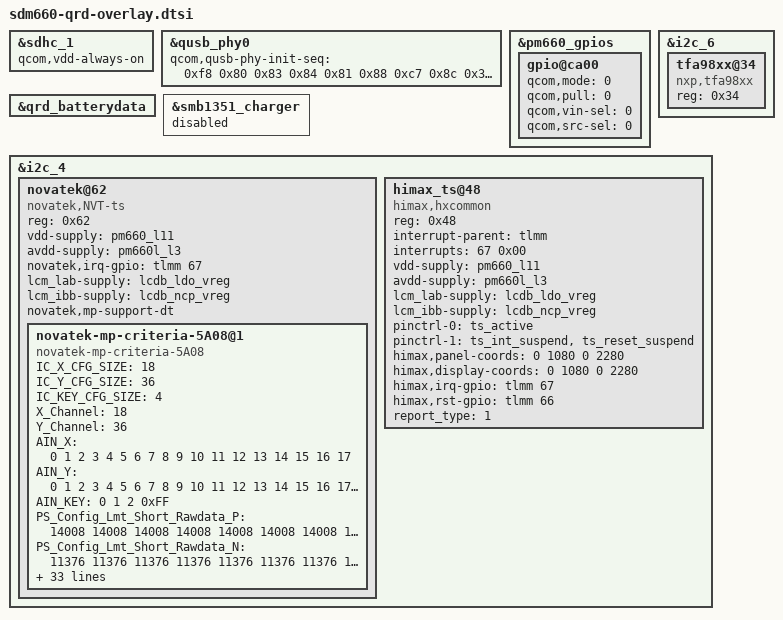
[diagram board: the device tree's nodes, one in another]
/* SPDX-License-Identifier: GPL-2.0 */

#include "sdm660-pinctrl-overlay.dtsi"
#include "sdm660-camera-sensor-qrd-overlay.dtsi"

&sdhc_1 {
	qcom,vdd-always-on;
};

&qusb_phy0 {
	qcom,qusb-phy-init-seq = <0xf8 0x80
				0x83 0x84
				0x81 0x88
				0xc7 0x8c
				0x30 0x08
				0x79 0x0c
				0x21 0x10
				0x14 0x9c
				0x9f 0x1c
				0x00 0x18>;
};

&pm660_gpios {
	gpio@ca00 {
		status = "okay";
		qcom,mode = <0>;
		qcom,pull = <0>;
		qcom,vin-sel = <0>;
		qcom,src-sel = <0>;
		/delete-property/ qcom,out-strength;
	};
};

&i2c_6 {
	tfa98xx@34 {
		compatible = "nxp,tfa98xx";
		reg = <0x34>;
	};
};

&qrd_batterydata {
	/delete-node/ qcom,qrd_msm8998_skuk_3000mah;

	#include "fg-gen3-batterydata-3292665_Huaqin_QL1650cos_5000mAh.dtsi"
};

&smb1351_charger {
	status = "disabled";
};

&i2c_4{
	status = "ok";

	/* Novatek device tree node */
	novatek@62 {
		compatible = "novatek,NVT-ts";
		reg = <0x62>;
		status = "ok";

		vdd-supply = <&pm660_l11>;    //VDDIO
		avdd-supply = <&pm660l_l3>;    //VDD

		novatek,irq-gpio = <&tlmm 67 0>;

		lcm_lab-supply = <&lcdb_ldo_vreg>;
		lcm_ibb-supply = <&lcdb_ncp_vreg>;

		/* MP */
		novatek,mp-support-dt;

		novatek-mp-criteria-5A08@1 {
			#address-cells = <1>;
			#size-cells = <0>;
			compatible = "novatek-mp-criteria-5A08";

			/* MP Config */
			IC_X_CFG_SIZE = <18>;
			IC_Y_CFG_SIZE = <36>;
			IC_KEY_CFG_SIZE = <4>;
			X_Channel = <18>;
			Y_Channel = <36>;
			AIN_X = <0 1 2 3 4 5 6 7 8 9 10 11 12 13 14 15 16 17>;
			AIN_Y = <0 1 2 3 4 5 6 7 8 9 10 11 12 13 14 15 16 17 18 19 20 21 22 23 24 25 26 27 28 29 30 31 32 33 34 35>;
			AIN_KEY = <0 1 2 0xFF>;

			/* MP Criteria */
			PS_Config_Lmt_Short_Rawdata_P = <
				14008 14008 14008 14008 14008 14008 14008 14008 14008 14008 14008 14008 14008 14008 14008 14008 14008 14008
				14008 14008 14008 14008 14008 14008 14008 14008 14008 14008 14008 14008 14008 14008 14008 14008 14008 14008
				14008 14008 14008 14008 14008 14008 14008 14008 14008 14008 14008 14008 14008 14008 14008 14008 14008 14008
				14008 14008 14008 14008 14008 14008 14008 14008 14008 14008 14008 14008 14008 14008 14008 14008 14008 14008
				14008 14008 14008 14008 14008 14008 14008 14008 14008 14008 14008 14008 14008 14008 14008 14008 14008 14008
				14008 14008 14008 14008 14008 14008 14008 14008 14008 14008 14008 14008 14008 14008 14008 14008 14008 14008
				14008 14008 14008 14008 14008 14008 14008 14008 14008 14008 14008 14008 14008 14008 14008 14008 14008 14008
				14008 14008 14008 14008 14008 14008 14008 14008 14008 14008 14008 14008 14008 14008 14008 14008 14008 14008
				14008 14008 14008 14008 14008 14008 14008 14008 14008 14008 14008 14008 14008 14008 14008 14008 14008 14008
				14008 14008 14008 14008 14008 14008 14008 14008 14008 14008 14008 14008 14008 14008 14008 14008 14008 14008
				14008 14008 14008 14008 14008 14008 14008 14008 14008 14008 14008 14008 14008 14008 14008 14008 14008 14008
				14008 14008 14008 14008 14008 14008 14008 14008 14008 14008 14008 14008 14008 14008 14008 14008 14008 14008
				14008 14008 14008 14008 14008 14008 14008 14008 14008 14008 14008 14008 14008 14008 14008 14008 14008 14008
				14008 14008 14008 14008 14008 14008 14008 14008 14008 14008 14008 14008 14008 14008 14008 14008 14008 14008
				14008 14008 14008 14008 14008 14008 14008 14008 14008 14008 14008 14008 14008 14008 14008 14008 14008 14008
				14008 14008 14008 14008 14008 14008 14008 14008 14008 14008 14008 14008 14008 14008 14008 14008 14008 14008
				14008 14008 14008 14008 14008 14008 14008 14008 14008 14008 14008 14008 14008 14008 14008 14008 14008 14008
				14008 14008 14008 14008 14008 14008 14008 14008 14008 14008 14008 14008 14008 14008 14008 14008 14008 14008
				14008 14008 14008 14008 14008 14008 14008 14008 14008 14008 14008 14008 14008 14008 14008 14008 14008 14008
				14008 14008 14008 14008 14008 14008 14008 14008 14008 14008 14008 14008 14008 14008 14008 14008 14008 14008
				14008 14008 14008 14008 14008 14008 14008 14008 14008 14008 14008 14008 14008 14008 14008 14008 14008 14008
				14008 14008 14008 14008 14008 14008 14008 14008 14008 14008 14008 14008 14008 14008 14008 14008 14008 14008
				14008 14008 14008 14008 14008 14008 14008 14008 14008 14008 14008 14008 14008 14008 14008 14008 14008 14008
				14008 14008 14008 14008 14008 14008 14008 14008 14008 14008 14008 14008 14008 14008 14008 14008 14008 14008
				14008 14008 14008 14008 14008 14008 14008 14008 14008 14008 14008 14008 14008 14008 14008 14008 14008 14008
				14008 14008 14008 14008 14008 14008 14008 14008 14008 14008 14008 14008 14008 14008 14008 14008 14008 14008
				14008 14008 14008 14008 14008 14008 14008 14008 14008 14008 14008 14008 14008 14008 14008 14008 14008 14008
				14008 14008 14008 14008 14008 14008 14008 14008 14008 14008 14008 14008 14008 14008 14008 14008 14008 14008
				14008 14008 14008 14008 14008 14008 14008 14008 14008 14008 14008 14008 14008 14008 14008 14008 14008 14008
				14008 14008 14008 14008 14008 14008 14008 14008 14008 14008 14008 14008 14008 14008 14008 14008 14008 14008
				14008 14008 14008 14008 14008 14008 14008 14008 14008 14008 14008 14008 14008 14008 14008 14008 14008 14008
				14008 14008 14008 14008 14008 14008 14008 14008 14008 14008 14008 14008 14008 14008 14008 14008 14008 14008
				14008 14008 14008 14008 14008 14008 14008 14008 14008 14008 14008 14008 14008 14008 14008 14008 14008 14008
				14008 14008 14008 14008 14008 14008 14008 14008 14008 14008 14008 14008 14008 14008 14008 14008 14008 14008
				14008 14008 14008 14008 14008 14008 14008 14008 14008 14008 14008 14008 14008 14008 14008 14008 14008 14008
				14008 14008 14008 14008 14008 14008 14008 14008 14008 14008 14008 14008 14008 14008 14008 14008 14008 14008
				20000 20000 20000>;

			PS_Config_Lmt_Short_Rawdata_N = <
				11376 11376 11376 11376 11376 11376 11376 11376 11376 11376 11376 11376 11376 11376 11376 11376 11376 11376
				11376 11376 11376 11376 11376 11376 11376 11376 11376 11376 11376 11376 11376 11376 11376 11376 11376 11376
				11376 11376 11376 11376 11376 11376 11376 11376 11376 11376 11376 11376 11376 11376 11376 11376 11376 11376
				11376 11376 11376 11376 11376 11376 11376 11376 11376 11376 11376 11376 11376 11376 11376 11376 11376 11376
				11376 11376 11376 11376 11376 11376 11376 11376 11376 11376 11376 11376 11376 11376 11376 11376 11376 11376
				11376 11376 11376 11376 11376 11376 11376 11376 11376 11376 11376 11376 11376 11376 11376 11376 11376 11376
				11376 11376 11376 11376 11376 11376 11376 11376 11376 11376 11376 11376 11376 11376 11376 11376 11376 11376
				11376 11376 11376 11376 11376 11376 11376 11376 11376 11376 11376 11376 11376 11376 11376 11376 11376 11376
				11376 11376 11376 11376 11376 11376 11376 11376 11376 11376 11376 11376 11376 11376 11376 11376 11376 11376
				11376 11376 11376 11376 11376 11376 11376 11376 11376 11376 11376 11376 11376 11376 11376 11376 11376 11376
				11376 11376 11376 11376 11376 11376 11376 11376 11376 11376 11376 11376 11376 11376 11376 11376 11376 11376
				11376 11376 11376 11376 11376 11376 11376 11376 11376 11376 11376 11376 11376 11376 11376 11376 11376 11376
				11376 11376 11376 11376 11376 11376 11376 11376 11376 11376 11376 11376 11376 11376 11376 11376 11376 11376
				11376 11376 11376 11376 11376 11376 11376 11376 11376 11376 11376 11376 11376 11376 11376 11376 11376 11376
				11376 11376 11376 11376 11376 11376 11376 11376 11376 11376 11376 11376 11376 11376 11376 11376 11376 11376
				11376 11376 11376 11376 11376 11376 11376 11376 11376 11376 11376 11376 11376 11376 11376 11376 11376 11376
				11376 11376 11376 11376 11376 11376 11376 11376 11376 11376 11376 11376 11376 11376 11376 11376 11376 11376
				11376 11376 11376 11376 11376 11376 11376 11376 11376 11376 11376 11376 11376 11376 11376 11376 11376 11376
				11376 11376 11376 11376 11376 11376 11376 11376 11376 11376 11376 11376 11376 11376 11376 11376 11376 11376
				11376 11376 11376 11376 11376 11376 11376 11376 11376 11376 11376 11376 11376 11376 11376 11376 11376 11376
				11376 11376 11376 11376 11376 11376 11376 11376 11376 11376 11376 11376 11376 11376 11376 11376 11376 11376
				11376 11376 11376 11376 11376 11376 11376 11376 11376 11376 11376 11376 11376 11376 11376 11376 11376 11376
				11376 11376 11376 11376 11376 11376 11376 11376 11376 11376 11376 11376 11376 11376 11376 11376 11376 11376
				11376 11376 11376 11376 11376 11376 11376 11376 11376 11376 11376 11376 11376 11376 11376 11376 11376 11376
				11376 11376 11376 11376 11376 11376 11376 11376 11376 11376 11376 11376 11376 11376 11376 11376 11376 11376
				11376 11376 11376 11376 11376 11376 11376 11376 11376 11376 11376 11376 11376 11376 11376 11376 11376 11376
				11376 11376 11376 11376 11376 11376 11376 11376 11376 11376 11376 11376 11376 11376 11376 11376 11376 11376
				11376 11376 11376 11376 11376 11376 11376 11376 11376 11376 11376 11376 11376 11376 11376 11376 11376 11376
				11376 11376 11376 11376 11376 11376 11376 11376 11376 11376 11376 11376 11376 11376 11376 11376 11376 11376
				11376 11376 11376 11376 11376 11376 11376 11376 11376 11376 11376 11376 11376 11376 11376 11376 11376 11376
				11376 11376 11376 11376 11376 11376 11376 11376 11376 11376 11376 11376 11376 11376 11376 11376 11376 11376
				11376 11376 11376 11376 11376 11376 11376 11376 11376 11376 11376 11376 11376 11376 11376 11376 11376 11376
				11376 11376 11376 11376 11376 11376 11376 11376 11376 11376 11376 11376 11376 11376 11376 11376 11376 11376
				11376 11376 11376 11376 11376 11376 11376 11376 11376 11376 11376 11376 11376 11376 11376 11376 11376 11376
				11376 11376 11376 11376 11376 11376 11376 11376 11376 11376 11376 11376 11376 11376 11376 11376 11376 11376
				11376 11376 11376 11376 11376 11376 11376 11376 11376 11376 11376 11376 11376 11376 11376 11376 11376 11376
				11550 11550 11550>;

			PS_Config_Lmt_Short_Diff_P = <
				6300 6300 6300 6300 6300 6300 6300 6300 6300 6300 6300 6300 6300 6300 6300 6300 6300 6300
				6300 6300 6300>;

			PS_Config_Lmt_Short_Diff_N = <
				0 0 0 0 0 0 0 0 0 0 0 0 0 0 0 0 0 0
				0 0 0>;

			PS_Config_Lmt_Short_Base_P = <
				2000 2000 2000 2000 2000 2000 2000 2000 2000 2000 2000 2000 2000 2000 2000 2000 2000 2000
				2000 2000 2000>;

			PS_Config_Lmt_Short_Base_N = <
				(-2000) (-2000) (-2000) (-2000) (-2000) (-2000) (-2000) (-2000) (-2000) (-2000) (-2000) (-2000) (-2000) (-2000) (-2000) (-2000) (-2000) (-2000)
				(-2000) (-2000) (-2000)>;

			PS_Config_Lmt_Open_Rawdata_P = <
				65535 6394 6393 6394 6394 6394 6394 65535 65535 65535 65535 6377 6377 6379 6379 6379 6379 65535
				3176 3307 3299 3291 3283 3271 3120 2645 2601 2558 2607 3086 3245 3261 3278 3310 3333 3205
				3141 3240 3236 3227 3219 3209 3137 3133 3109 3099 3132 3132 3210 3226 3240 3274 3298 3208
				3131 3213 3212 3204 3197 3188 3118 3115 3094 3053 3086 3084 3160 3172 3190 3223 3247 3172
				3162 3220 3217 3209 3203 3196 3127 3123 3102 3070 3100 3097 3171 3185 3200 3234 3259 3211
				3187 3231 3227 3221 3217 3210 3141 3139 3118 3073 3103 3099 3172 3184 3200 3233 3259 3225
				3251 3264 3262 3256 3249 3244 3177 3175 3157 3127 3156 3154 3229 3244 3257 3287 3314 3309
				3221 3219 3217 3216 3210 3206 3141 3145 3123 3083 3116 3111 3182 3193 3208 3237 3264 3275
				3232 3212 3214 3211 3205 3202 3140 3123 3120 3086 3093 3107 3175 3188 3199 3230 3257 3287
				3247 3214 3216 3217 3212 3208 3148 3130 3128 3074 3082 3095 3161 3172 3186 3213 3241 3283
				3279 3235 3236 3236 3233 3230 3170 3158 3155 3124 3129 3142 3211 3223 3234 3260 3288 3341
				3234 3174 3173 3177 3174 3173 3116 3108 3104 3069 3067 3079 3144 3153 3167 3188 3222 3287
				3232 3157 3158 3161 3159 3160 3103 3096 3090 3055 3053 3059 3125 3134 3146 3161 3193 3282
				3229 3148 3147 3154 3151 3154 3096 3095 3084 3033 3031 3037 3105 3110 3125 3138 3169 3261
				3251 3184 3152 3156 3157 3163 3101 3105 3095 3070 3059 3070 3142 3147 3159 3175 3208 3310
				3207 3400 3124 3106 3106 3113 3053 3059 3048 3005 3000 3008 3077 3079 3093 3107 3302 3247
				3188 3371 3366 3372 3104 3086 3028 3034 3021 2986 2989 2991 3056 3059 3245 3382 3404 3236
				3177 3349 3346 3353 3355 3093 3008 3006 3002 2941 2936 2947 3011 3190 3326 3339 3356 3200
				3186 3336 3319 3317 3309 3313 2949 2946 2935 2977 2958 2959 3318 3312 3314 3318 3335 3187
				3127 3272 3256 3256 3248 3251 2887 2883 2887 2903 2885 2884 3245 3241 3242 3245 3259 3115
				3113 3247 3229 3230 3225 3230 2864 2859 2857 2875 2850 2853 3220 3212 3212 3213 3225 3094
				3088 3217 3202 3201 3197 3203 2833 2831 2823 2834 2807 2811 3181 3172 3172 3174 3180 3053
				3072 3196 3177 3177 3176 3184 2814 2811 2799 2849 2825 2830 3198 3191 3190 3190 3195 3076
				3011 3127 3111 3110 3110 3117 2745 2748 2732 2759 2737 2742 3112 3103 3101 3102 3104 2990
				2982 3089 3068 3061 3061 3069 2695 2697 2676 2712 2693 2696 3068 3060 3057 3058 3062 2954
				2959 3064 3047 3037 3039 3048 2672 2679 2653 2662 2657 2654 3028 3019 3014 3018 3017 2908
				2942 3039 3021 3011 3014 3023 2645 2655 2621 2667 2669 2661 3035 3027 3024 3025 3026 2923
				2863 2960 2943 2931 2934 2933 2564 2583 2541 2556 2578 2568 2937 2936 2933 2934 2933 2828
				2828 2924 2905 2895 2898 2896 2526 2529 2501 2512 2535 2526 2895 2896 2895 2893 2893 2787
				2792 2883 2865 2853 2856 2852 2479 2486 2458 2442 2468 2459 2829 2832 2832 2831 2831 2724
				2725 2813 2794 2782 2782 2778 2403 2411 2381 2412 2435 2427 2798 2802 2803 2802 2804 2702
				2686 2773 2757 2745 2744 2738 2365 2373 2342 2346 2372 2365 2739 2743 2743 2742 2743 2640
				2643 2728 2710 2699 2698 2690 2317 2320 2291 2300 2327 2321 2696 2701 2703 2700 2703 2600
				2605 2690 2675 2664 2660 2651 2281 2284 2253 2233 2263 2255 2630 2635 2640 2637 2639 2535
				2550 2635 2617 2605 2602 2593 2218 2219 2191 2208 2239 2233 2606 2614 2623 2620 2620 2518
				2616 2753 2732 2723 2718 2713 2334 2331 2304 2301 2332 2330 2705 2711 2723 2719 2719 2525
				13000 13000 13000>;

			PS_Config_Lmt_Open_Rawdata_N = <
				(-65535) 3221 3221 3221 3221 3221 3221 (-65535) (-65535) (-65535) (-65535) 3213 3213 3214 3214 3214 3214 (-65535)
				1600 1666 1662 1658 1654 1648 1572 1333 1310 1288 1314 1555 1635 1643 1651 1667 1679 1615
				1582 1632 1630 1626 1622 1616 1580 1578 1566 1561 1578 1578 1617 1625 1632 1649 1661 1616
				1577 1619 1618 1614 1611 1606 1571 1569 1559 1538 1555 1554 1592 1598 1607 1624 1636 1598
				1593 1622 1621 1617 1614 1610 1575 1573 1563 1547 1561 1560 1598 1605 1612 1629 1642 1618
				1606 1627 1626 1623 1620 1617 1582 1581 1571 1548 1563 1561 1598 1604 1612 1629 1642 1625
				1638 1645 1644 1640 1637 1634 1601 1600 1590 1575 1590 1589 1627 1634 1641 1656 1669 1667
				1623 1622 1621 1620 1617 1615 1582 1584 1573 1553 1570 1567 1603 1608 1616 1631 1644 1650
				1628 1618 1619 1617 1615 1613 1582 1573 1572 1555 1558 1565 1599 1606 1611 1627 1641 1656
				1636 1619 1620 1620 1618 1616 1586 1577 1576 1549 1552 1559 1592 1598 1605 1619 1633 1654
				1652 1630 1630 1630 1629 1627 1597 1591 1590 1574 1576 1583 1617 1624 1629 1642 1656 1683
				1629 1599 1598 1601 1599 1598 1570 1566 1564 1546 1545 1551 1584 1588 1595 1606 1623 1656
				1628 1591 1591 1593 1591 1592 1563 1560 1556 1539 1538 1541 1574 1579 1585 1592 1609 1653
				1627 1586 1585 1589 1587 1589 1559 1559 1554 1528 1527 1530 1564 1567 1574 1581 1596 1643
				1638 1604 1588 1590 1590 1593 1562 1564 1559 1546 1541 1547 1583 1585 1591 1599 1616 1667
				1616 1713 1574 1565 1564 1568 1538 1541 1535 1514 1511 1515 1550 1551 1558 1565 1664 1636
				1606 1698 1696 1699 1563 1555 1525 1529 1522 1504 1506 1507 1540 1541 1634 1704 1715 1630
				1601 1687 1685 1689 1690 1558 1515 1514 1512 1482 1479 1485 1517 1607 1676 1682 1691 1612
				1605 1681 1672 1671 1667 1669 1486 1484 1478 1500 1490 1491 1671 1669 1670 1671 1680 1606
				1575 1648 1640 1640 1636 1638 1454 1452 1454 1462 1453 1453 1634 1633 1633 1635 1642 1569
				1568 1636 1627 1627 1625 1627 1443 1440 1439 1448 1436 1437 1622 1618 1618 1618 1625 1559
				1556 1621 1613 1612 1611 1614 1427 1426 1422 1427 1414 1416 1602 1598 1598 1599 1602 1538
				1548 1610 1600 1600 1600 1604 1417 1416 1410 1435 1423 1426 1611 1607 1607 1607 1610 1550
				1517 1575 1567 1567 1567 1570 1383 1384 1376 1390 1379 1381 1568 1563 1562 1563 1564 1506
				1502 1556 1546 1542 1542 1546 1358 1359 1348 1366 1357 1358 1545 1542 1540 1540 1542 1488
				1491 1544 1535 1530 1531 1535 1346 1350 1336 1341 1339 1337 1525 1521 1518 1520 1520 1465
				1482 1531 1522 1517 1519 1523 1332 1338 1320 1343 1344 1340 1529 1525 1523 1524 1524 1472
				1442 1491 1483 1477 1478 1478 1292 1301 1280 1288 1299 1294 1479 1479 1478 1478 1477 1425
				1425 1473 1464 1458 1460 1459 1273 1274 1260 1265 1277 1272 1458 1459 1458 1457 1457 1404
				1406 1452 1443 1437 1439 1437 1249 1252 1238 1230 1243 1239 1425 1426 1426 1426 1426 1372
				1373 1417 1408 1402 1402 1399 1211 1214 1199 1215 1227 1223 1410 1412 1412 1411 1413 1361
				1353 1397 1389 1383 1382 1379 1191 1195 1180 1182 1195 1192 1380 1382 1382 1381 1382 1330
				1331 1374 1365 1359 1359 1355 1167 1169 1154 1159 1172 1169 1358 1361 1361 1360 1362 1310
				1312 1355 1348 1342 1340 1336 1149 1151 1135 1125 1140 1136 1325 1327 1330 1328 1329 1277
				1285 1327 1318 1312 1311 1306 1117 1118 1104 1112 1128 1125 1313 1317 1321 1320 1320 1268
				1318 1387 1376 1372 1369 1367 1176 1174 1161 1159 1175 1174 1363 1366 1372 1370 1370 1272
				6500 6500 6500>;

			PS_Config_Lmt_FW_Rawdata_P = <
				65535 1697 1715 1707 1674 1697 1720 65535 65535 65535 65535 1708 1717 1670 1685 1687 1691 65535
				1676 1661 1670 1672 1669 1668 1687 1670 1694 1698 1674 1704 1676 1668 1665 1678 1663 1672
				1684 1694 1687 1702 1676 1663 1671 1710 1686 1692 1662 1663 1685 1716 1659 1696 1686 1699
				1682 1697 1656 1692 1677 1635 1690 1691 1686 1671 1651 1655 1680 1699 1662 1680 1671 1690
				1678 1699 1713 1702 1669 1692 1703 1681 1671 1688 1673 1661 1690 1709 1651 1674 1676 1699
				1711 1702 1682 1726 1691 1684 1712 1698 1679 1709 1678 1693 1717 1715 1691 1697 1684 1703
				1674 1682 1678 1684 1666 1646 1682 1682 1668 1655 1672 1654 1670 1688 1645 1650 1699 1652
				1716 1685 1674 1687 1698 1685 1705 1702 1688 1691 1660 1697 1686 1683 1683 1692 1669 1682
				1662 1670 1704 1688 1681 1697 1689 1662 1678 1704 1671 1672 1680 1706 1669 1677 1701 1687
				1684 1678 1709 1691 1674 1732 1735 1689 1665 1715 1711 1689 1693 1696 1662 1677 1696 1713
				1681 1677 1677 1693 1689 1663 1667 1663 1705 1674 1663 1690 1683 1670 1673 1679 1691 1684
				1695 1702 1684 1680 1705 1678 1676 1679 1688 1678 1668 1671 1660 1687 1689 1677 1686 1703
				1697 1688 1692 1686 1702 1713 1705 1693 1682 1676 1697 1680 1693 1704 1689 1686 1703 1676
				1661 1653 1649 1672 1673 1670 1671 1666 1678 1673 1663 1684 1667 1667 1674 1664 1678 1676
				1660 1696 1686 1705 1694 1697 1681 1685 1677 1716 1686 1709 1703 1679 1695 1681 1714 1706
				1700 1690 1679 1703 1709 1725 1714 1699 1692 1700 1697 1697 1702 1710 1683 1698 1701 1684
				1646 1691 1668 1668 1665 1672 1674 1653 1687 1671 1670 1680 1658 1678 1678 1674 1674 1663
				1697 1677 1664 1696 1684 1714 1708 1702 1689 1693 1687 1689 1685 1676 1721 1696 1693 1700
				1650 1657 1669 1649 1660 1659 1663 1659 1675 1641 1679 1651 1644 1655 1692 1670 1636 1689
				1668 1678 1688 1681 1705 1675 1689 1716 1687 1687 1681 1674 1667 1664 1693 1676 1680 1701
				1658 1658 1701 1694 1672 1685 1683 1681 1686 1673 1703 1702 1698 1712 1691 1661 1678 1708
				1705 1665 1686 1688 1704 1676 1687 1680 1682 1685 1700 1684 1679 1688 1687 1690 1720 1672
				1686 1697 1670 1698 1699 1700 1700 1695 1676 1701 1715 1686 1693 1687 1679 1692 1689 1667
				1658 1682 1679 1657 1673 1694 1657 1647 1664 1648 1683 1675 1683 1678 1668 1664 1690 1681
				1655 1677 1670 1671 1662 1673 1667 1672 1686 1670 1673 1675 1666 1670 1673 1690 1657 1673
				1694 1721 1709 1684 1653 1654 1682 1699 1691 1692 1697 1692 1682 1675 1688 1726 1709 1670
				1694 1679 1643 1680 1719 1711 1691 1678 1661 1675 1694 1703 1673 1673 1705 1699 1685 1675
				1683 1673 1681 1691 1693 1687 1702 1677 1675 1706 1691 1685 1689 1693 1687 1712 1699 1687
				1699 1718 1686 1677 1680 1685 1669 1688 1676 1709 1698 1711 1695 1692 1692 1713 1673 1670
				1674 1677 1671 1675 1688 1682 1698 1671 1675 1664 1702 1692 1704 1695 1669 1709 1709 1691
				1723 1689 1699 1697 1688 1692 1693 1698 1692 1689 1700 1699 1710 1705 1691 1693 1698 1693
				1677 1693 1660 1668 1687 1666 1675 1672 1672 1668 1696 1692 1676 1663 1656 1680 1680 1696
				1634 1666 1688 1691 1694 1683 1690 1665 1677 1675 1707 1676 1689 1692 1682 1674 1674 1676
				1707 1707 1711 1674 1671 1685 1679 1678 1682 1683 1706 1711 1695 1698 1683 1706 1672 1690
				1678 1684 1693 1675 1649 1658 1675 1666 1665 1678 1649 1636 1680 1684 1645 1669 1679 1677
				1684 1677 1672 1682 1661 1666 1673 1664 1674 1673 1665 1668 1669 1665 1677 1659 1665 1671
				2000 2000 2000>;

			PS_Config_Lmt_FW_Rawdata_N = <
				(-65535) 727 735 732 718 727 737 (-65535) (-65535) (-65535) (-65535) 732 736 716 722 723 725 (-65535)
				718 712 716 717 715 715 723 716 726 728 718 730 718 715 713 719 713 716
				722 726 723 730 718 713 716 733 723 725 712 713 722 735 711 727 723 728
				721 727 710 725 719 701 724 725 723 716 707 709 720 728 712 720 716 724
				719 728 734 730 715 725 730 720 716 723 717 712 724 732 708 717 718 728
				733 730 721 740 725 722 734 728 720 733 719 726 736 735 725 727 722 730
				717 721 719 722 714 705 721 721 715 709 716 709 716 724 705 707 728 708
				735 722 718 723 728 722 731 729 724 725 711 727 723 721 721 725 715 721
				712 716 730 723 720 727 724 712 719 730 716 717 720 731 715 719 729 723
				722 719 732 725 717 742 744 724 714 735 733 724 726 727 712 719 727 734
				720 719 719 726 724 713 714 713 731 717 713 724 721 716 717 720 725 722
				727 729 722 720 731 719 718 719 724 719 715 716 711 723 724 719 723 730
				727 724 725 723 729 734 731 725 721 718 727 720 725 730 724 722 730 718
				712 708 707 716 717 716 716 714 719 717 713 722 714 714 717 713 719 718
				712 727 722 731 726 727 721 722 719 736 722 732 730 720 727 720 734 731
				729 724 719 730 733 739 735 728 725 728 727 727 730 733 721 728 729 722
				705 725 715 715 714 717 717 708 723 716 716 720 711 719 719 717 717 713
				727 719 713 727 722 734 732 729 724 725 723 724 722 718 738 727 725 729
				707 710 715 707 711 711 713 711 718 703 720 708 705 709 725 716 701 724
				715 719 723 720 731 718 724 735 723 723 720 718 715 713 726 718 720 729
				711 711 729 726 716 722 721 720 723 717 730 729 728 734 725 712 719 732
				731 714 723 724 730 718 723 720 721 722 728 722 719 723 723 724 737 717
				722 727 716 728 728 728 729 726 718 729 735 722 725 723 720 725 724 714
				711 721 720 710 717 726 710 706 713 706 721 718 721 719 715 713 724 720
				709 719 716 716 712 717 714 717 722 716 717 718 714 716 717 724 710 717
				726 738 732 722 709 709 721 728 725 725 727 725 721 718 723 740 732 716
				726 720 704 720 737 733 725 719 712 718 726 730 717 717 731 728 722 718
				721 717 720 725 726 723 729 719 718 731 725 722 724 725 723 734 728 723
				728 736 723 719 720 722 715 724 718 732 728 733 726 725 725 734 717 716
				718 719 716 718 724 721 728 716 718 713 729 725 730 726 715 733 732 725
				738 724 728 727 723 725 726 728 725 724 729 728 733 731 725 726 728 726
				719 725 711 715 723 714 718 716 717 715 727 725 718 713 710 720 720 727
				700 714 723 725 726 721 724 714 719 718 731 718 724 725 721 717 717 718
				731 732 733 718 716 722 720 719 721 721 731 733 727 728 721 731 716 724
				719 722 726 718 707 710 718 714 714 719 707 701 720 722 705 715 720 719
				722 719 717 721 712 714 717 713 718 717 713 715 715 714 719 711 713 716
				400 400 400>;

			PS_Config_Lmt_FW_CC_P = <
				65535 111 109 108 108 106 106 65535 65535 65535 65535 110 111 112 112 112 115 65535
				122 115 113 112 112 111 110 110 109 111 110 111 112 112 113 114 115 122
				119 113 111 110 109 108 108 107 107 114 113 113 114 115 116 116 118 124
				120 113 112 111 110 110 108 108 108 112 111 111 112 112 114 114 116 122
				119 113 111 110 110 109 108 108 107 112 111 112 112 113 114 114 116 122
				121 114 113 112 112 111 110 109 109 111 110 110 111 111 113 113 115 120
				118 112 111 110 109 109 108 107 107 113 112 113 113 114 115 116 117 123
				119 113 112 111 110 110 109 108 108 112 111 111 112 112 114 114 115 121
				118 112 111 110 110 109 108 108 107 113 111 112 112 113 114 114 115 121
				120 114 113 113 112 111 111 110 110 112 110 111 111 112 113 113 114 119
				117 112 111 110 110 109 109 108 107 115 112 112 113 114 114 115 116 122
				117 112 111 111 110 109 109 108 108 116 111 112 112 113 114 114 115 120
				117 112 111 110 110 109 109 108 107 116 112 111 111 112 113 114 114 119
				120 115 114 114 113 112 112 113 111 115 112 110 111 111 112 113 113 118
				116 111 110 110 109 109 108 110 107 118 113 112 113 113 114 115 115 120
				117 113 113 112 111 111 111 112 110 116 113 111 111 111 113 113 113 118
				117 113 112 111 111 111 111 112 109 117 113 112 112 112 112 113 114 118
				118 114 113 113 112 111 111 112 110 115 110 109 109 110 110 111 112 115
				115 112 111 110 109 109 109 109 107 118 113 112 112 113 113 114 115 118
				116 112 112 111 110 110 110 110 110 117 111 111 110 111 112 113 113 116
				116 113 112 111 111 110 110 110 109 117 111 111 111 111 112 112 113 117
				117 114 114 113 112 112 112 111 111 116 109 110 109 110 110 111 111 115
				115 111 111 110 110 109 110 109 108 119 112 113 112 112 113 114 114 118
				116 112 112 111 110 110 111 111 109 116 110 111 110 110 111 112 112 115
				116 112 112 111 111 110 111 111 109 115 111 110 110 110 111 111 112 115
				117 114 114 113 113 113 113 114 111 114 111 110 110 110 110 111 111 114
				116 113 113 112 111 111 112 113 110 113 114 113 112 112 112 113 114 117
				116 114 113 112 112 112 112 114 111 109 112 112 111 110 111 112 112 115
				116 113 113 112 111 111 113 113 110 109 112 111 110 110 111 111 113 115
				118 115 115 114 113 113 114 115 112 107 110 110 109 109 110 110 110 113
				115 113 112 111 110 110 111 111 109 110 113 113 111 111 112 113 114 116
				116 114 113 113 112 112 113 114 111 109 112 112 110 110 111 112 112 114
				117 115 114 113 112 112 114 114 111 110 113 113 111 111 112 112 113 115
				118 115 115 115 114 113 117 117 113 109 112 112 109 109 110 110 111 113
				116 114 113 113 112 112 116 115 112 112 116 117 112 113 114 114 114 116
				114 113 112 112 112 113 116 115 111 111 115 116 112 112 113 113 113 113
				38 38 38>;

			PS_Config_Lmt_FW_CC_N = <
				(-65535) 65 64 64 63 63 62 (-65535) (-65535) (-65535) (-65535) 65 65 66 66 66 68 (-65535)
				72 68 66 66 66 65 64 64 64 65 65 65 66 66 66 67 68 72
				70 66 65 65 64 64 63 63 63 67 66 66 67 67 68 68 69 73
				70 66 66 65 65 64 64 63 63 66 65 65 66 66 67 67 68 72
				70 66 65 65 64 64 63 63 63 66 65 66 66 66 67 67 68 72
				71 67 66 66 66 65 64 64 64 65 65 65 65 65 66 66 67 71
				69 66 65 65 64 64 63 63 63 67 66 66 67 67 68 68 69 72
				70 66 66 65 65 64 64 64 63 66 65 65 66 66 67 67 68 71
				69 66 65 65 64 64 64 63 63 66 65 66 66 66 67 67 68 71
				70 67 66 66 66 65 65 64 64 66 64 65 65 66 66 66 67 70
				69 66 65 65 64 64 64 63 63 67 66 66 66 67 67 67 68 71
				69 66 65 65 64 64 64 64 63 68 65 66 66 66 67 67 67 70
				68 66 65 65 64 64 64 64 63 68 66 65 65 66 66 67 67 70
				70 67 67 67 66 66 66 66 65 68 66 65 65 65 66 66 67 69
				68 65 65 64 64 64 64 65 63 69 66 66 66 66 67 67 68 70
				69 66 66 66 65 65 65 66 64 68 66 65 65 65 66 66 67 69
				69 66 66 65 65 65 65 66 64 69 66 66 66 66 66 66 67 69
				69 67 67 66 66 65 65 66 64 67 65 64 64 64 65 65 66 68
				68 65 65 65 64 64 64 64 63 69 66 66 66 66 66 67 67 69
				68 66 66 65 65 64 65 65 65 69 65 65 65 65 66 66 66 68
				68 66 66 65 65 65 65 65 64 69 65 65 65 65 66 66 66 68
				69 67 67 66 66 66 66 65 65 68 64 64 64 64 65 65 65 67
				67 65 65 65 64 64 64 64 64 70 66 66 66 66 66 67 67 69
				68 66 66 65 65 65 65 65 64 68 65 65 65 65 65 66 66 68
				68 66 66 65 65 65 65 65 64 68 65 65 64 65 65 65 66 68
				69 67 67 66 66 66 66 67 65 67 65 65 64 64 65 65 65 67
				68 66 66 66 65 65 66 66 65 67 67 66 66 66 66 66 67 69
				68 67 66 66 66 66 66 67 65 64 66 66 65 65 65 66 66 68
				68 66 66 66 65 65 66 66 65 64 66 65 65 65 65 65 66 68
				69 68 68 67 67 67 67 67 66 63 65 65 64 64 64 65 65 66
				67 66 66 65 65 65 65 65 64 65 66 66 65 65 66 66 67 68
				68 67 67 66 66 66 66 67 65 64 66 66 65 65 65 66 66 67
				69 67 67 66 66 66 67 67 65 64 67 66 65 65 66 66 66 68
				69 68 68 67 67 67 69 69 67 64 66 66 64 64 65 65 65 66
				68 67 66 66 66 66 68 67 66 66 68 69 66 66 67 67 67 68
				67 66 65 66 66 66 68 67 65 65 68 68 66 66 66 66 66 67
				9 9 9>;

			PS_Config_Lmt_FW_CC_I_P = <
				25 25 25 25 25 25 25 25 25 25 25 25 25 25 25 25 25 25
				25 25 25>;

			PS_Config_Lmt_FW_CC_I_N = <
				0 0 0 0 0 0 0 0 0 0 0 0 0 0 0 0 0 0
				0 0 0>;

			PS_Config_Lmt_FW_CC_Q_P = <
				25 25 25 25 25 25 25 25 25 25 25 25 25 25 25 25 25 25
				25 25 25>;

			PS_Config_Lmt_FW_CC_Q_N = <
				0 0 0 0 0 0 0 0 0 0 0 0 0 0 0 0 0 0
				0 0 0>;

			PS_Config_Lmt_FW_Diff_P = <
				65535 50 50 50 50 50 50 65535 65535 65535 65535 50 50 50 50 50 50 65535
				50 50 50 50 50 50 50 50 50 50 50 50 50 50 50 50 50 50
				50 50 50 50 50 50 50 50 50 50 50 50 50 50 50 50 50 50
				50 50 50 50 50 50 50 50 50 50 50 50 50 50 50 50 50 50
				50 50 50 50 50 50 50 50 50 50 50 50 50 50 50 50 50 50
				50 50 50 50 50 50 50 50 50 50 50 50 50 50 50 50 50 50
				50 50 50 50 50 50 50 50 50 50 50 50 50 50 50 50 50 50
				50 50 50 50 50 50 50 50 50 50 50 50 50 50 50 50 50 50
				50 50 50 50 50 50 50 50 50 50 50 50 50 50 50 50 50 50
				50 50 50 50 50 50 50 50 50 50 50 50 50 50 50 50 50 50
				50 50 50 50 50 50 50 50 50 50 50 50 50 50 50 50 50 50
				50 50 50 50 50 50 50 50 50 50 50 50 50 50 50 50 50 50
				50 50 50 50 50 50 50 50 50 50 50 50 50 50 50 50 50 50
				50 50 50 50 50 50 50 50 50 50 50 50 50 50 50 50 50 50
				50 50 50 50 50 50 50 50 50 50 50 50 50 50 50 50 50 50
				50 50 50 50 50 50 50 50 50 50 50 50 50 50 50 50 50 50
				50 50 50 50 50 50 50 50 50 50 50 50 50 50 50 50 50 50
				50 50 50 50 50 50 50 50 50 50 50 50 50 50 50 50 50 50
				50 50 50 50 50 50 50 50 50 50 50 50 50 50 50 50 50 50
				50 50 50 50 50 50 50 50 50 50 50 50 50 50 50 50 50 50
				50 50 50 50 50 50 50 50 50 50 50 50 50 50 50 50 50 50
				50 50 50 50 50 50 50 50 50 50 50 50 50 50 50 50 50 50
				50 50 50 50 50 50 50 50 50 50 50 50 50 50 50 50 50 50
				50 50 50 50 50 50 50 50 50 50 50 50 50 50 50 50 50 50
				50 50 50 50 50 50 50 50 50 50 50 50 50 50 50 50 50 50
				50 50 50 50 50 50 50 50 50 50 50 50 50 50 50 50 50 50
				50 50 50 50 50 50 50 50 50 50 50 50 50 50 50 50 50 50
				50 50 50 50 50 50 50 50 50 50 50 50 50 50 50 50 50 50
				50 50 50 50 50 50 50 50 50 50 50 50 50 50 50 50 50 50
				50 50 50 50 50 50 50 50 50 50 50 50 50 50 50 50 50 50
				50 50 50 50 50 50 50 50 50 50 50 50 50 50 50 50 50 50
				50 50 50 50 50 50 50 50 50 50 50 50 50 50 50 50 50 50
				50 50 50 50 50 50 50 50 50 50 50 50 50 50 50 50 50 50
				50 50 50 50 50 50 50 50 50 50 50 50 50 50 50 50 50 50
				50 50 50 50 50 50 50 50 50 50 50 50 50 50 50 50 50 50
				50 50 50 50 50 50 50 50 50 50 50 50 50 50 50 50 50 50
				50 50 50>;

			PS_Config_Lmt_FW_Diff_N = <
				(-65535) (-50) (-50) (-50) (-50) (-50) (-50) (-65535) (-65535) (-65535) (-65535) (-50) (-50) (-50) (-50) (-50) (-50) (-65535)
				(-50) (-50) (-50) (-50) (-50) (-50) (-50) (-50) (-50) (-50) (-50) (-50) (-50) (-50) (-50) (-50) (-50) (-50)
				(-50) (-50) (-50) (-50) (-50) (-50) (-50) (-50) (-50) (-50) (-50) (-50) (-50) (-50) (-50) (-50) (-50) (-50)
				(-50) (-50) (-50) (-50) (-50) (-50) (-50) (-50) (-50) (-50) (-50) (-50) (-50) (-50) (-50) (-50) (-50) (-50)
				(-50) (-50) (-50) (-50) (-50) (-50) (-50) (-50) (-50) (-50) (-50) (-50) (-50) (-50) (-50) (-50) (-50) (-50)
				(-50) (-50) (-50) (-50) (-50) (-50) (-50) (-50) (-50) (-50) (-50) (-50) (-50) (-50) (-50) (-50) (-50) (-50)
				(-50) (-50) (-50) (-50) (-50) (-50) (-50) (-50) (-50) (-50) (-50) (-50) (-50) (-50) (-50) (-50) (-50) (-50)
				(-50) (-50) (-50) (-50) (-50) (-50) (-50) (-50) (-50) (-50) (-50) (-50) (-50) (-50) (-50) (-50) (-50) (-50)
				(-50) (-50) (-50) (-50) (-50) (-50) (-50) (-50) (-50) (-50) (-50) (-50) (-50) (-50) (-50) (-50) (-50) (-50)
				(-50) (-50) (-50) (-50) (-50) (-50) (-50) (-50) (-50) (-50) (-50) (-50) (-50) (-50) (-50) (-50) (-50) (-50)
				(-50) (-50) (-50) (-50) (-50) (-50) (-50) (-50) (-50) (-50) (-50) (-50) (-50) (-50) (-50) (-50) (-50) (-50)
				(-50) (-50) (-50) (-50) (-50) (-50) (-50) (-50) (-50) (-50) (-50) (-50) (-50) (-50) (-50) (-50) (-50) (-50)
				(-50) (-50) (-50) (-50) (-50) (-50) (-50) (-50) (-50) (-50) (-50) (-50) (-50) (-50) (-50) (-50) (-50) (-50)
				(-50) (-50) (-50) (-50) (-50) (-50) (-50) (-50) (-50) (-50) (-50) (-50) (-50) (-50) (-50) (-50) (-50) (-50)
				(-50) (-50) (-50) (-50) (-50) (-50) (-50) (-50) (-50) (-50) (-50) (-50) (-50) (-50) (-50) (-50) (-50) (-50)
				(-50) (-50) (-50) (-50) (-50) (-50) (-50) (-50) (-50) (-50) (-50) (-50) (-50) (-50) (-50) (-50) (-50) (-50)
				(-50) (-50) (-50) (-50) (-50) (-50) (-50) (-50) (-50) (-50) (-50) (-50) (-50) (-50) (-50) (-50) (-50) (-50)
				(-50) (-50) (-50) (-50) (-50) (-50) (-50) (-50) (-50) (-50) (-50) (-50) (-50) (-50) (-50) (-50) (-50) (-50)
				(-50) (-50) (-50) (-50) (-50) (-50) (-50) (-50) (-50) (-50) (-50) (-50) (-50) (-50) (-50) (-50) (-50) (-50)
				(-50) (-50) (-50) (-50) (-50) (-50) (-50) (-50) (-50) (-50) (-50) (-50) (-50) (-50) (-50) (-50) (-50) (-50)
				(-50) (-50) (-50) (-50) (-50) (-50) (-50) (-50) (-50) (-50) (-50) (-50) (-50) (-50) (-50) (-50) (-50) (-50)
				(-50) (-50) (-50) (-50) (-50) (-50) (-50) (-50) (-50) (-50) (-50) (-50) (-50) (-50) (-50) (-50) (-50) (-50)
				(-50) (-50) (-50) (-50) (-50) (-50) (-50) (-50) (-50) (-50) (-50) (-50) (-50) (-50) (-50) (-50) (-50) (-50)
				(-50) (-50) (-50) (-50) (-50) (-50) (-50) (-50) (-50) (-50) (-50) (-50) (-50) (-50) (-50) (-50) (-50) (-50)
				(-50) (-50) (-50) (-50) (-50) (-50) (-50) (-50) (-50) (-50) (-50) (-50) (-50) (-50) (-50) (-50) (-50) (-50)
				(-50) (-50) (-50) (-50) (-50) (-50) (-50) (-50) (-50) (-50) (-50) (-50) (-50) (-50) (-50) (-50) (-50) (-50)
				(-50) (-50) (-50) (-50) (-50) (-50) (-50) (-50) (-50) (-50) (-50) (-50) (-50) (-50) (-50) (-50) (-50) (-50)
				(-50) (-50) (-50) (-50) (-50) (-50) (-50) (-50) (-50) (-50) (-50) (-50) (-50) (-50) (-50) (-50) (-50) (-50)
				(-50) (-50) (-50) (-50) (-50) (-50) (-50) (-50) (-50) (-50) (-50) (-50) (-50) (-50) (-50) (-50) (-50) (-50)
				(-50) (-50) (-50) (-50) (-50) (-50) (-50) (-50) (-50) (-50) (-50) (-50) (-50) (-50) (-50) (-50) (-50) (-50)
				(-50) (-50) (-50) (-50) (-50) (-50) (-50) (-50) (-50) (-50) (-50) (-50) (-50) (-50) (-50) (-50) (-50) (-50)
				(-50) (-50) (-50) (-50) (-50) (-50) (-50) (-50) (-50) (-50) (-50) (-50) (-50) (-50) (-50) (-50) (-50) (-50)
				(-50) (-50) (-50) (-50) (-50) (-50) (-50) (-50) (-50) (-50) (-50) (-50) (-50) (-50) (-50) (-50) (-50) (-50)
				(-50) (-50) (-50) (-50) (-50) (-50) (-50) (-50) (-50) (-50) (-50) (-50) (-50) (-50) (-50) (-50) (-50) (-50)
				(-50) (-50) (-50) (-50) (-50) (-50) (-50) (-50) (-50) (-50) (-50) (-50) (-50) (-50) (-50) (-50) (-50) (-50)
				(-50) (-50) (-50) (-50) (-50) (-50) (-50) (-50) (-50) (-50) (-50) (-50) (-50) (-50) (-50) (-50) (-50) (-50)
				(-50) (-50) (-50)>;
			PS_Config_Diff_Test_Frame = <50>;
		};
	};

	himax_ts@48 {
		compatible = "himax,hxcommon";
		reg = <0x48>;
		interrupt-parent = <&tlmm>;
		interrupts = <67 0x00>;
		vdd-supply = <&pm660_l11>;
		avdd-supply = <&pm660l_l3>;
		lcm_lab-supply = <&lcdb_ldo_vreg>;
		lcm_ibb-supply = <&lcdb_ncp_vreg>;
		pinctrl-names = "pmx_ts_active", "pmx_ts_suspend";
		pinctrl-0 = <&ts_active>;
		pinctrl-1 = <&ts_int_suspend &ts_reset_suspend>;
		himax,panel-coords = <0 1080 0 2280>;
		himax,display-coords = <0 1080 0 2280>;
		himax,irq-gpio = <&tlmm 67 0x00>;
		himax,rst-gpio = <&tlmm 66 0x00>;
		report_type = <1>;
	};
};
